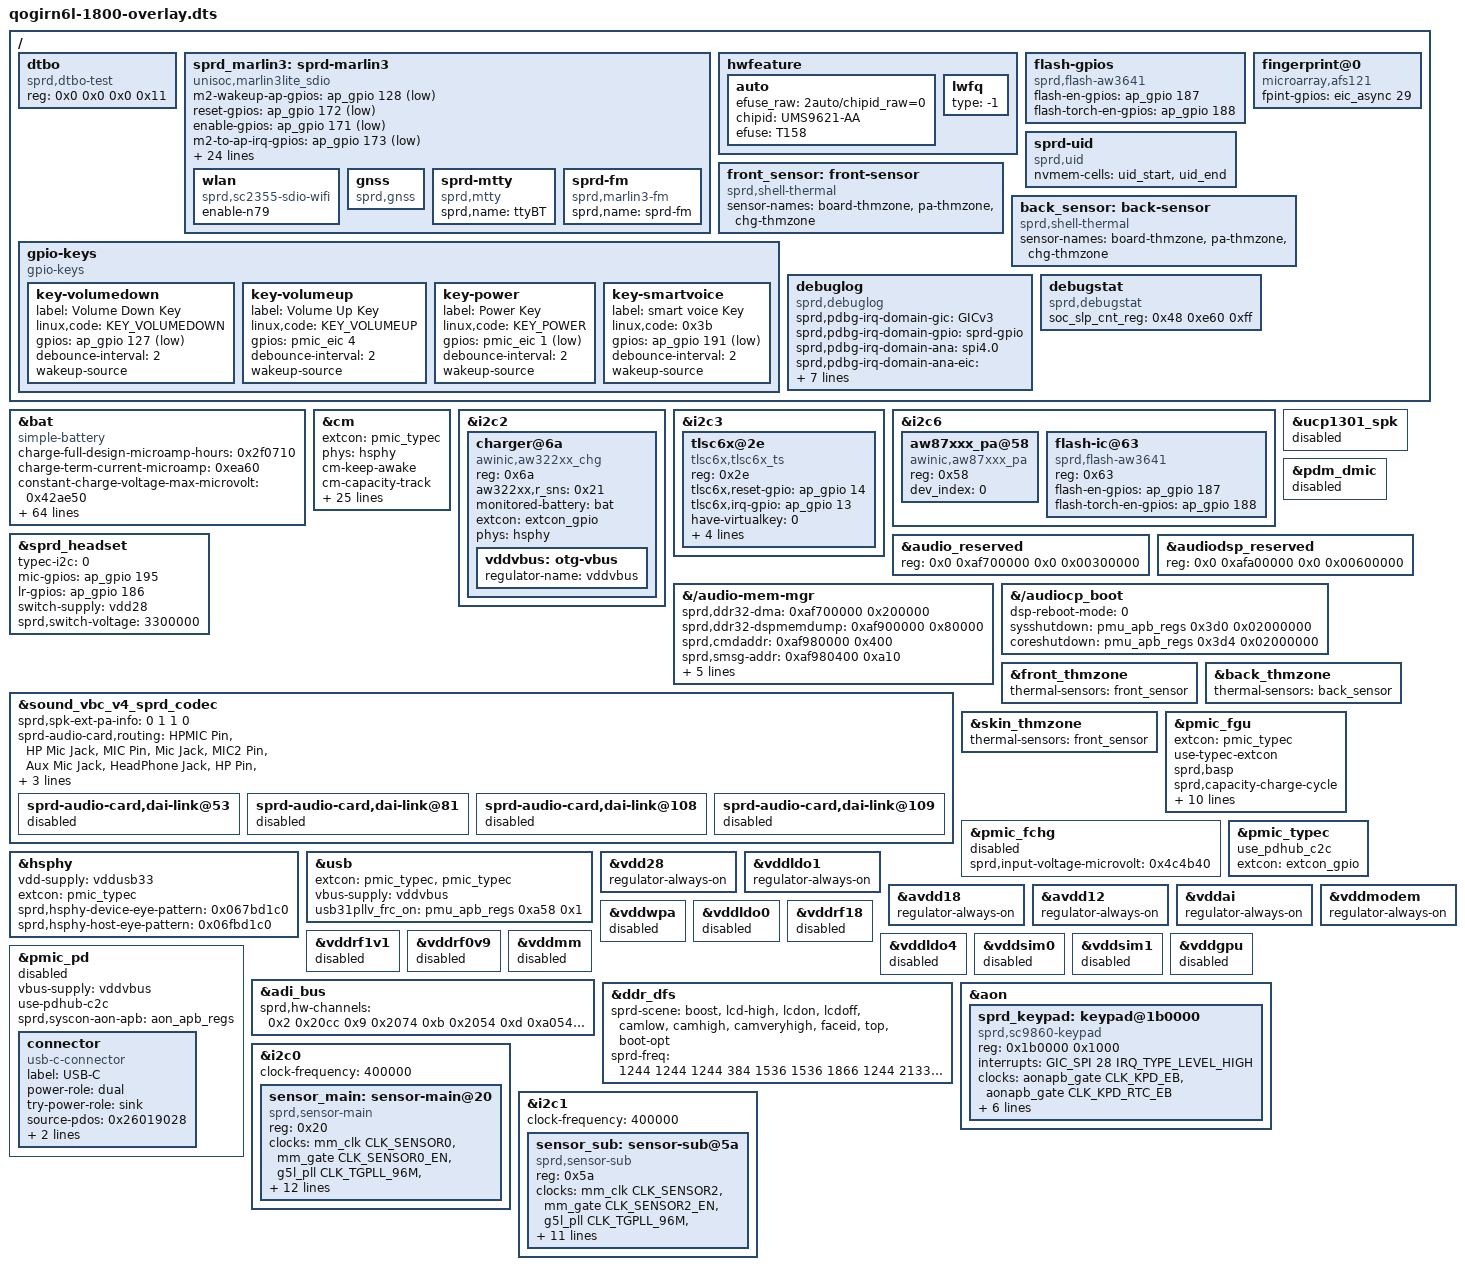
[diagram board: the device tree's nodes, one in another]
// SPDX-License-Identifier: (Licenseref-Unisoc-General-1.0 OR GPL-2.0-only)
/*
 * qogirn6l-1800-overlay.dts - UMS9621 board ID 0x1800 overlay
 *
 * Reconstructed from the device live FDT using
 * motorola-sprd-andriod-14-release-uoa34 ums9621-1h10-overlay.dts as the
 * board template. Base: ums9621-base.dtb (model/compatible/sc-id match the
 * device exactly). Values in hex are taken verbatim from the device FDT.
 */

/dts-v1/;
/plugin/;
#include <dt-bindings/gpio/gpio.h>
#include <dt-bindings/interrupt-controller/arm-gic.h>
#include <dt-bindings/clock/sprd,ums9621-clk.h>
#include <dt-bindings/usb/pd.h>
#include <dt-bindings/input/input.h>
#include "lcd/lcd_nt36528_kti_mipi_hdp.dtsi"
#include "lcd/lcd_g40396_truly_mipi_fhd.dtsi"
#include "lcd/amoled_g3655fp103ff_visionox_mipi_fhd.dtsi"
#include "lcd/lcd_td4320_truly_mipi_fhd.dtsi"
#include "lcd/lcd_dummy_mipi.dtsi"
#include "lcd/lcd_sprd_st73xx_mipi_hdp.dtsi"
#include "reserved-memory/ums9621-1h10-overlay.dtsi"
#include <dt-bindings/mfd/sprd,ump9620-regs.h>
#include <dt-bindings/mfd/sprd,ump9620-mask.h>
#include "wcn/wcn_modules.h"
#include "wcn/interface/wcn-sdio-register.dtsi"
#include "wcn/chip/wcn-marlin3lite-umw2652-register.dtsi"

/* NOTE: bat2/bat3/virtual_typec/pa5g-sensor/pdbg remain from the base;
 * the device build removed them, but /delete-node/ cannot reference base
 * labels from a /plugin/ overlay at compile time. They are unused on this board. */
/ {
	fragment {
		target-path = "/";
		__overlay__ {
			dtbo: dtbo {
				compatible = "sprd,dtbo-test";
				reg = <0x0 0x0 0x0 0x11>;
			};

			sprd_marlin3: sprd-marlin3 {
				compatible = "unisoc,marlin3lite_sdio";
				m2-wakeup-ap-gpios = <&ap_gpio 128 GPIO_ACTIVE_LOW>;
				reset-gpios = <&ap_gpio 172 GPIO_ACTIVE_LOW>;
				enable-gpios = <&ap_gpio 171 GPIO_ACTIVE_LOW>;
				m2-to-ap-irq-gpios = <&ap_gpio 173 GPIO_ACTIVE_LOW>;
				avdd12-supply = <&vddwcn>;
				avdd33-supply = <&vddwifipa>;
				dcxo18-supply = <&vddsim2>;
				clock-names = "clk_32k", "source", "enable";
				clocks = <&aonapb_gate CLK_AUX0>,
					 <&ext_32k>,
					 <&aonapb_gate CLK_AUX0_EB>;
				extcon = <&sdio1>;
				sdhci-name = <&sdio1>;
				sprd,check-emmc-ufs = "need_to_check_emmc_or_ufs";
				sprd,btwf-file-name = "/dev/block/by-name/wcnmodem";
				sprd,gnss-file-name = "/vendor/firmware/gnssmodem.bin";
				sprd,gnss-dump-reg-number = <0x04>;
				sprd,gnss-dump-packet-size = <0x8000>;
				sprd,gnss-firmware-max-size = <0x2b000>;
				sprd,gnss-cp-start-addr = <0x40a50000>;
				adma-tx;
				adma-rx;
				btwf-wakeup-lock;
				n79-mode-support;
				avdd12-bound-wbreq = <REG_ANA_LDO_XTL_EN10 MASK_ANA_LDO_VDDWCN_EXT_XTL3_EN 0x0 MASK_ANA_LDO_VDDWCN_EXT_XTL3_EN>;
				avdd33-bound-wbreq = <REG_ANA_LDO_XTL_EN11 MASK_ANA_LDO_VDDWIFIPA_EXT_XTL3_EN 0x0 MASK_ANA_LDO_VDDWIFIPA_EXT_XTL3_EN>;

				wlan {
					compatible = "sprd,sc2355-sdio-wifi";
					enable-n79;
				};

				gnss {
					compatible = "sprd,gnss";
				};

				sprd-mtty {
					compatible = "sprd,mtty";
					sprd,name = "ttyBT";
				};

				sprd-fm {
					compatible = "sprd,marlin3-fm";
					sprd,name = "sprd-fm";
				};
			};

			hwfeature {
				auto {
					efuse_raw = "2auto/chipid_raw=0";
					chipid = "UMS9621-AA";
					efuse = "T158";
				};

				lwfq {
					type = "-1";
				};
			};

			flash-gpios {
				compatible = "sprd,flash-aw3641";
				flash-en-gpios = <&ap_gpio 187 0>;
				flash-torch-en-gpios = <&ap_gpio 188 0>;
			};

			fingerprint@0 {
				compatible = "microarray,afs121";
				fpint-gpios = <&eic_async 29 0>;
			};

			sprd-uid {
				compatible = "sprd,uid";
				nvmem-cells = <&uid_start>, <&uid_end>;
			};

			front_sensor: front-sensor {
				compatible = "sprd,shell-thermal";
				#thermal-sensor-cells = <0>;
				sensor-names = "board-thmzone", "pa-thmzone", "chg-thmzone";
			};

			back_sensor: back-sensor {
				compatible = "sprd,shell-thermal";
				#thermal-sensor-cells = <0>;
				sensor-names = "board-thmzone", "pa-thmzone", "chg-thmzone";
			};

			gpio-keys {
				compatible = "gpio-keys";

				key-volumedown {
					label = "Volume Down Key";
					linux,code = <KEY_VOLUMEDOWN>;
					gpios = <&ap_gpio 127 GPIO_ACTIVE_LOW>;
					debounce-interval = <2>;
					wakeup-source;
				};

				key-volumeup {
					label = "Volume Up Key";
					linux,code = <KEY_VOLUMEUP>;
					gpios = <&pmic_eic 4 GPIO_ACTIVE_HIGH>;
					debounce-interval = <2>;
					wakeup-source;
				};

				key-power {
					label = "Power Key";
					linux,code = <KEY_POWER>;
					gpios = <&pmic_eic 1 GPIO_ACTIVE_LOW>;
					debounce-interval = <2>;
					wakeup-source;
				};

				key-smartvoice {
					label = "smart voice Key";
					linux,code = <0x3b>;
					gpios = <&ap_gpio 191 GPIO_ACTIVE_LOW>;
					debounce-interval = <2>;
					wakeup-source;
				};
			};

			debuglog {
				compatible = "sprd,debuglog";
				sprd,pdbg-irq-domain-gic = "GICv3";
				sprd,pdbg-irq-domain-gpio = "sprd-gpio";
				sprd,pdbg-irq-domain-ana = "spi4.0";
				sprd,pdbg-irq-domain-ana-eic = "64400000.spi:pmic@0:gpio@280";
				sprd,pdbg-irq-domain-ap-eic-dbnc = "64200000.gpio";
				sprd,pdbg-irq-domain-ap-eic-latch = "64200080.gpio";
				sprd,pdbg-irq-domain-ap-eic-async = "642000a0.gpio";
			};

			debugstat {
				compatible = "sprd,debugstat";
				soc_slp_cnt_reg = <0x48 0xe60 0xff>;
			};
		};
	};
};

&bat {
	compatible = "simple-battery";
	status = "okay";
	charge-full-design-microamp-hours = <0x2f0710>;
	charge-term-current-microamp = <0xea60>;
	constant-charge-voltage-max-microvolt = <0x42ae50>;
	factory-internal-resistance-micro-ohms = <0x249f0>;
	voltage-min-design-microvolt = <0x346228>;
	fullbatt-voltage = <0x421210>;
	fullbatt-current = <0x1d4c0>;
	first-fullbatt-current = <0x249f0>;
	fullbatt-track-end-vol = <0x41fe88>;
	fullbatt-track-end-cur = <0x1fbd0>;
	first-calib-voltage = <0x34db40>;
	first-calib-capacity = <0x32>;
	batt-ovp-threshold-microvolt = <0x493e00>;
	fullbatt-voltage-offset-microvolt = <0xafc8>;
	ir-cv-offset-microvolt = <0x186a0>;
	ir-rc-micro-ohms = <0x4e20>;
	ir-us-upper-limit-microvolt = <0x44aa20>;
	ocv-capacity-celsius = <0x19>;
	ocv-capacity-table-0 = <0x420270 0x64>, <0x408f58 0x5f>, <0x3fa8e0 0x5a>,
		<0x3e9f40 0x55>, <0x3dd808 0x50>, <0x3cfd48 0x4b>, <0x3c4998 0x46>,
		<0x3b7a90 0x41>, <0x3ad680 0x3c>, <0x3a2e88 0x37>, <0x399e00 0x32>,
		<0x393870 0x2d>, <0x386d50 0x28>, <0x37f050 0x23>, <0x379678 0x1e>,
		<0x374088 0x19>, <0x36b3e8 0x14>, <0x363300 0x0f>, <0x358b08 0x0a>,
		<0x34db40 0x05>, <0x341fc0 0x00>;
	voltage-temp-table = <0x108a60 0x320>, <0xee098 0x352>, <0xd3ea0 0x384>,
		<0xbac48 0x3b6>, <0xa3160 0x3e8>, <0x8d9a0 0x41a>, <0x7a508 0x44c>,
		<0x68fb0 0x47e>, <0x5a168 0x4b0>, <0x4ce78 0x4e2>, <0x41eb0 0x514>,
		<0x38658 0x546>, <0x30188 0x578>, <0x29428 0x5aa>, <0x23668 0x5dc>,
		<0x1e848 0x60e>, <0x1a5e0 0x640>, <0x16b48 0x672>;
	capacity-temp-table = <0x19 0x64>, <0x0a 0x61>, <0xfffffff6 0x5a>;
	resistance-temp-table = <0x19 0x64>, <0x0a 0xf3>, <0xfffffff6 0x1d4>;
	charge-sdp-current-microamp = <0x7a120 0x7a120>;
	charge-dcp-current-microamp = <0x192d50 0x192d50>;
	charge-cdp-current-microamp = <0x192d50 0x192d50>;
	charge-unknown-current-microamp = <0x192d50 0x192d50>;
	cap-calib-energy-density-ocv-table = <0x331df0 0x39fbc0>, <0x3f52f0 0x426030>;
	cap-track-energy-density-ocv-table = <0x33e140 0x38cb10>;
	dcp-jeita-temp-table = <0x3e8 0x3e8 0x00 0x423920>, <0x47e 0x47e 0x9eb10 0x423920>,
		<0x5aa 0x5aa 0x192d50 0x42ae50>, <0x60e 0x60e 0x9eb10 0x423920>;
	sdp-jeita-temp-table = <0x3e8 0x3e8 0x00 0x423920>, <0x47e 0x47e 0x7a120 0x423920>,
		<0x5aa 0x5aa 0x7a120 0x42ae50>, <0x60e 0x60e 0x7a120 0x423920>;
	cdp-jeita-temp-table = <0x3e8 0x3e8 0x00 0x423920>, <0x47e 0x47e 0x9eb10 0x423920>,
		<0x5aa 0x5aa 0x192d50 0x42ae50>, <0x60e 0x60e 0x7a120 0x423920>;
	unknown-jeita-temp-table = <0x3e8 0x3e8 0x00 0x423920>, <0x47e 0x47e 0x9eb10 0x423920>,
		<0x5aa 0x5aa 0x192d50 0x42ae50>, <0x60e 0x60e 0x9eb10 0x423920>;
};

&cm {
	extcon = <&pmic_typec>;
	phys = <&hsphy>;
	cm-keep-awake;
	cm-capacity-track;
	monitored-battery = <&bat>;
	cm-cap-remap-table = <0x01 0x02 0x03 0x02 0x03 0x02 0x62 0x63 0x02 0x63 0x64 0x03>;
	cm-charge-voltage-drop = <0xaae60>;
	cm-charge-voltage-max = <0x5d1420>;
	cm-thermal-zone = "board-thmzone";
	cm-one-cap-time = <0x1e>;
	cm-tickle-time-out = <0x5dc>;
	cm-shutdown-voltage = <0x2f4d60>;
	cm-wdt-interval = <0x3c>;
	cm-discharging-max = <0x2932e0>;
	cm-charging-max = <0x1499700>;
	cm-battery-temp-diff = <0x64>;
	cm-battery-hot = <0x320>;
	cm-battery-cold-in-minus;
	cm-battery-cold = <0xc8>;
	cm-fuel-gauge = "sc27xx-fgu";
	cm-chargers = "aw322xx_charger";
	cm-fullbatt-capacity = <0x64>;
	cm-fullbatt-vchkdrop-volt = <0x13880>;
	cm-fullbatt-vchkdrop-ms = <0x7530>;
	cm-battery-stat = <0x02>;
	cm-poll-interval = <0x3a98>;
	cm-poll-mode = <0x02>;
	cm-name = "battery";
	status = "okay";
};

&i2c2 {
	status = "okay";

	charger@6a {
		compatible = "awinic,aw322xx_chg";
		reg = <0x6a>;
		aw322xx,r_sns = <0x21>;
		monitored-battery = <&bat>;
		extcon = <&extcon_gpio>;
		phys = <&hsphy>;

		vddvbus: otg-vbus {
			regulator-name = "vddvbus";
		};
	};
};

&i2c3 {
	status = "okay";

	tlsc6x@2e {
		compatible = "tlsc6x,tlsc6x_ts";
		reg = <0x2e>;
		tlsc6x,reset-gpio = <&ap_gpio 14 GPIO_ACTIVE_HIGH>;
		tlsc6x,irq-gpio = <&ap_gpio 13 GPIO_ACTIVE_HIGH>;
		have-virtualkey = <0>;
		virtualkeys = <400 1010 60 40 240 1010 60 40 80 1010 60 40>;
		TP_MAX_X = <320>;
		TP_MAX_Y = <480>;
	};
};

&i2c6 {
	aw87xxx_pa@58 {
		compatible = "awinic,aw87xxx_pa";
		reg = <0x58>;
		dev_index = <0>;
		status = "okay";
	};

	flash-ic@63 {
		compatible = "sprd,flash-aw3641";
		reg = <0x63>;
		flash-en-gpios = <&ap_gpio 187 0>;
		flash-torch-en-gpios = <&ap_gpio 188 0>;
	};
};

/* This board uses the I2C AW87xxx hook, not the reference-board codecs. */
&ucp1301_spk {
	status = "disabled";
};

&pdm_dmic {
	status = "disabled";
};

/* The analog Type-C mux is GPIO controlled; low selects USB D+/D-. */
&sprd_headset {
	typec-i2c = <0>;
	mic-gpios = <&ap_gpio 195 GPIO_ACTIVE_HIGH>;
	lr-gpios = <&ap_gpio 186 GPIO_ACTIVE_HIGH>;
	switch-supply = <&vdd28>;
	sprd,switch-voltage = <3300000>;
};

/* The shipped DSP firmware uses the 0xaf700000/0xafa00000 DDR layout. */
&audio_reserved {
	reg = <0x0 0xaf700000 0x0 0x00300000>;
};

&audiodsp_reserved {
	reg = <0x0 0xafa00000 0x0 0x00600000>;
};

&{/audio-mem-mgr} {
	sprd,ddr32-dma = <0xaf700000 0x200000>;
	sprd,ddr32-dspmemdump = <0xaf900000 0x80000>;
	sprd,cmdaddr = <0xaf980000 0x400>;
	sprd,smsg-addr = <0xaf980400 0xa10>;
	sprd,shmaddr-aud-str = <0xaf980e10 0x400>;
	sprd,shmaddr-dsp-vbc = <0xaf981210 0x1000>;
	sprd,shmaddr-nxp = <0xaf982210 0x800>;
	sprd,shmaddr-dsp-smartpa = <0xaf982a10 0x1000>;
	sprd,shmaddr-reg-dump = <0xaf983a10 0x400>;
};

&{/audiocp_boot} {
	dsp-reboot-mode = <0>;
	sysshutdown = <&pmu_apb_regs 0x3d0 0x02000000>;
	coreshutdown = <&pmu_apb_regs 0x3d4 0x02000000>;
};

&sound_vbc_v4_sprd_codec {
	sprd,spk-ext-pa-info = <0 1 1 0>;
	sprd-audio-card,routing =
		"HPMIC Pin", "HP Mic Jack",
		"MIC Pin", "Mic Jack",
		"MIC2 Pin", "Aux Mic Jack",
		"HeadPhone Jack", "HP Pin",
		"Ext Spk", "HP Pin",
		"Ext Spk1", "HP Pin",
		"Ext Spk", "SPK Pin",
		"Ext Spk1", "SPK Pin",
		"Ext Ear", "EAR Pin",
		"Ext Ear", "SPK Pin",
		"Ext Ear", "HP Pin";

	sprd-audio-card,dai-link@53 {
		status = "disabled";
	};
	sprd-audio-card,dai-link@81 {
		status = "disabled";
	};
	sprd-audio-card,dai-link@108 {
		status = "disabled";
	};
	sprd-audio-card,dai-link@109 {
		status = "disabled";
	};
};

&front_thmzone {
	thermal-sensors = <&front_sensor>;
};

&back_thmzone {
	thermal-sensors = <&back_sensor>;
};

&skin_thmzone {
	thermal-sensors = <&front_sensor>;
};

&pmic_fgu {
extcon = <&pmic_typec>;
use-typec-extcon;
sprd,basp;
sprd,capacity-charge-cycle;
sprd,capacity-boot-calibration;
sprd,capacity-sleep-calibration;
sprd,relax-current-threshold = <0x1e>;
sprd,relax-counter-threshold = <0x244>;
phys = <&hsphy>;
fgu-capacity-track;
sprd,comp-resistance-mohm = <0x0b>;
sprd,calib-resistance-micro-ohms = <0x12f2>;
monitored-battery = <&bat>;
bat-detect-gpio = <&pmic_eic 3 0>;
};

&pmic_fchg {
sprd,input-voltage-microvolt = <0x4c4b40>;
status = "disable";
};

&pmic_typec {
status = "okay";
use_pdhub_c2c;
extcon = <&extcon_gpio>;
};

&hsphy {
vdd-supply = <&vddusb33>;
extcon = <&pmic_typec>;
sprd,hsphy-device-eye-pattern = <0x067bd1c0>;
sprd,hsphy-host-eye-pattern = <0x06fbd1c0>;
status = "okay";
};

&usb {
	extcon = <&pmic_typec>, <&pmic_typec>;
	vbus-supply = <&vddvbus>;
	usb31pllv_frc_on = <&pmu_apb_regs 0xa58 0x1>;
	status = "okay";
};

/* Preserve the stock board power constraints during late regulator cleanup. */
&vdd28 {
	regulator-always-on;
};

&vddldo1 {
	regulator-always-on;
};

&avdd18 {
	regulator-always-on;
};

&avdd12 {
	regulator-always-on;
};

&vddai {
	regulator-always-on;
};

&vddmodem {
	regulator-always-on;
};

/*
 * The other half of the stock regulator recipe, ported fragment-for-fragment
 * from the stock DTBO: ten unused rails are disabled there. Carrying only
 * the always-on half (or neither) left the regulator state machine diverged
 * from stock, which showed up as the ~32 s recovery blackout (unused-rail
 * cleanup cutting live rails) and as a system-boot watchdog loop.
 */
&vddwpa {
	status = "disabled";
};

&vddldo0 {
	status = "disabled";
};

&vddrf18 {
	status = "disabled";
};

&vddrf1v1 {
	status = "disabled";
};

&vddrf0v9 {
	status = "disabled";
};

&vddldo4 {
	status = "disabled";
};

&vddmm {
	status = "disabled";
};

&vddsim0 {
	status = "disabled";
};

&vddsim1 {
	status = "disabled";
};

&vddgpu {
	status = "disabled";
};

/* Stock keeps the PMIC PD controller off on this board (charging goes
 * through the type-C/extcon path) and describes the USB-C connector. */
&pmic_pd {
	status = "disable";
	vbus-supply = <&vddvbus>;
	use-pdhub-c2c;
	sprd,syscon-aon-apb = <&aon_apb_regs>;

	connector {
		compatible = "usb-c-connector";
		label = "USB-C";
		power-role = "dual";
		try-power-role = "sink";
		source-pdos = <0x26019028>;
		sink-pdos = <0x401912c 0xc0dc213c>;
		op-sink-microwatt = <0x989680>;
	};
};

/* Stock ADC channel map for the PMIC ADI bus (charger detection reads). */
&adi_bus {
	sprd,hw-channels = <
		0x2 0x20cc 0x9 0x2074 0xb 0x2054 0xd 0xa054
		0xf 0xa180 0x11 0xa1a0 0x13 0x244c 0x15 0xa0e8
		0x17 0x2044 0x19 0xa074 0x1b 0xa044 0x1e 0x2020
		0x20 0x217c 0x21 0x2188 0x22 0x21b8 0x23 0x21ac>;
};

/* Stock DDR DFS scene table. */
&ddr_dfs {
	sprd-scene = "boost", "lcd-high", "lcdon", "lcdoff", "camlow",
		     "camhigh", "camveryhigh", "faceid", "top", "boot-opt";
	sprd-freq = <1244 1244 1244 384 1536 1536 1866 1244 2133 1866>;
};

/* Physical keypad, from the working stock FDT. */
&aon {
	sprd_keypad: keypad@1b0000 {
		compatible = "sprd,sc9860-keypad";
		reg = <0x1b0000 0x1000>;
		interrupts = <GIC_SPI 28 IRQ_TYPE_LEVEL_HIGH>;
		clock-names = "enable", "rtc";
		clocks = <&aonapb_gate CLK_KPD_EB>,
			 <&aonapb_gate CLK_KPD_RTC_EB>;
		keypad,num-rows = <4>;
		keypad,num-columns = <7>;
		debounce-interval = <5>;
		linux,keymap = <
			0x0000009e 0x00010004 0x00020007 0x0003000a
			0x0004020b 0x00060067 0x01000161 0x0102006c
			0x01030003 0x01040006 0x01050009 0x0106000b
			0x0300008b 0x030100a9 0x03030002 0x03040005
			0x03050008 0x03060037 0x01010069 0x0005006a
		>;
		wakeup-source;
		status = "okay";
	};
};

/* Camera wiring from the stock DTBO (fragments 31 and 32). */
&i2c0 {
	status = "okay";
	clock-frequency = <400000>;
	sensor_main: sensor-main@20 {
		compatible = "sprd,sensor-main";
		reg = <0x20>;
		clock-names = "clk_src", "sensor_eb", "clk_96m", "clk_64m", "clk_51m2", "clk_48m", "clk_26m";
		clocks = <&mm_clk CLK_SENSOR0>, <&mm_gate CLK_SENSOR0_EN>,
			<&g5l_pll CLK_TGPLL_96M>, <&g5l_pll CLK_TGPLL_64M>,
			<&g5l_pll CLK_TGPLL_51M2>, <&g5l_pll CLK_TGPLL_48M>, <&ext_26m>;
		vddio-supply = <&vddcamio>;
		vddcama-supply = <&vddcama0>;
		vddcamd-supply = <&vddcamd0>;
		vddcammot-supply = <&vddcammot0>;
		reset-gpios = <&ap_gpio 39 GPIO_ACTIVE_HIGH>;
		power-down-gpios = <&ap_gpio 45 GPIO_ACTIVE_HIGH>;
		sprd,phyid = <4>;
		csi = <&csi1>;
		power-domains = <&mm_domain>;
	};
};
&i2c1 {
	status = "okay";
	clock-frequency = <400000>;
	sensor_sub: sensor-sub@5a {
		compatible = "sprd,sensor-sub";
		reg = <0x5a>;
		clock-names = "clk_src", "sensor_eb", "clk_96m", "clk_64m", "clk_51m2", "clk_48m", "clk_26m";
		clocks = <&mm_clk CLK_SENSOR2>, <&mm_gate CLK_SENSOR2_EN>,
			<&g5l_pll CLK_TGPLL_96M>, <&g5l_pll CLK_TGPLL_64M>,
			<&g5l_pll CLK_TGPLL_51M2>, <&g5l_pll CLK_TGPLL_48M>, <&ext_26m>;
		vddio-supply = <&vddcamio>;
		vddcama-supply = <&vddcama1>;
		vddcamd-supply = <&vddcamd1>;
		reset-gpios = <&ap_gpio 40 GPIO_ACTIVE_HIGH>;
		power-down-gpios = <&ap_gpio 46 GPIO_ACTIVE_HIGH>;
		sprd,phyid = <3>;
		csi = <&csi1>;
		power-domains = <&mm_domain>;
	};
};
